# DA1469x register map
Vendor: Dialog; Series: DA1469x; File version: 1.2
CPU: CM33 r1p0, little endian, no MPU, FPU, 3 interrupt priority bits
Registers are 32-bit, read-write, reset 0x0 unless marked. A register's access mark holds for its fields unless they carry their own. Offsets are from the block's base; [hi:lo] are bit positions; {n}, {i} and the like mark numbered series; 'fields as' and 'values as' point back to an identical list.

## PDC — PDC registers
Base 0x50000200
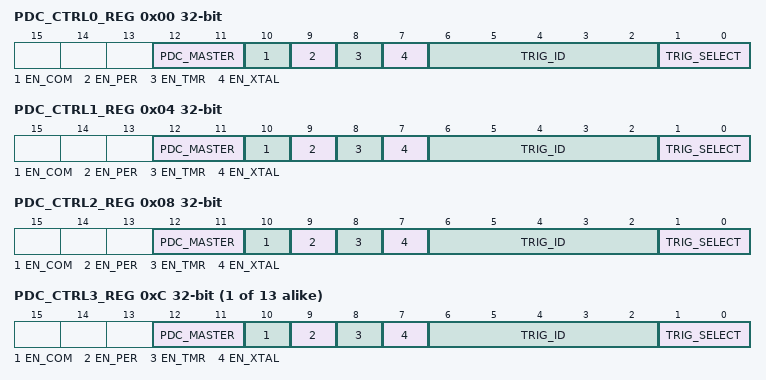
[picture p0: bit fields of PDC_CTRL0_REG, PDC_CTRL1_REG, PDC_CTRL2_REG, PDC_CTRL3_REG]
0x00 PDC_CTRL0_REG — PDC control register
  [12:11] PDC_MASTER — Chooses which master is triggered when waking up 0x0: entry is disabled. 0x1: PD_SYS is woken up and CM33 is triggered 0x2: PD_RAD is woken up and CMAC is triggered 0x3: PD_COM is woken up and SNC is triggered
  [10] EN_COM — If set, enables PD_COM for GPIO access. This bit is implied when PDC_MASTER=SNC
  [9] EN_PER — If set, enables PD_PER
  [8] EN_TMR — If set, enables PD_TMR
  [7] EN_XTAL — If set, the XTAL32M will be started
  [6:2] TRIG_ID — Selects which individual bit from the selected bank is used for wakup. For the peripheral banks, selected with TRIG_SELECT = 0x2 or 0x3, only the lower 4 bits are considered.
  [1:0] TRIG_SELECT — Selects which bank is used as wakeup trigger When TRIG_SELECT is 0x0, selects GPIO port0 through the WAKEUP block. When TRIG_SELECT is 0x1, selects GPIO port1 through the WAKEUP block. When TRIG_SELECT is 0x2 or 0x3, selects the peripheral IRQ. peripheral IRQ table: 0x0: Timer 0x1: Timer2 0x2: Timer3 0x3: Timer4 0x4: RTC Alarm/Rollover 0x5: RTC Timer 0x6: CMAC Timer OR wake up from CMAC debugger 0x7: Motor Controller 0x8: XTAL32MRDY_IRQ 0x9: RFDIAG_IRQ 0xA: CMAC2SYS_IRQ OR VBUS Present IRQ OR JTAG present OR Debounced IO 0xB: Sensor Node Controller 0xC to 0xE: reserved 0xF: Software trigger only
0x04 PDC_CTRL1_REG — PDC control register
  [12:11] PDC_MASTER — Chooses which master is triggered when waking up 0x0: entry is disabled. 0x1: PD_SYS is woken up and CM33 is triggered 0x2: PD_RAD is woken up and CMAC is triggered 0x3: PD_COM is woken up and SNC is triggered
  [10] EN_COM — If set, enables PD_COM for GPIO access. This bit is implied when PDC_MASTER=SNC
  [9] EN_PER — If set, enables PD_PER
  [8] EN_TMR — If set, enables PD_TMR
  [7] EN_XTAL — If set, the XTAL32M will be started
  [6:2] TRIG_ID — For description, see PDC_CTRL0_REG.TRIG_ID
  [1:0] TRIG_SELECT — For description, see PDC_CTRL0_REG.TRIG_SELECT
0x08 PDC_CTRL2_REG — PDC control register
  [12:11] PDC_MASTER — Chooses which master is triggered when waking up 0x0: entry is disabled. 0x1: PD_SYS is woken up and CM33 is triggered 0x2: PD_RAD is woken up and CMAC is triggered 0x3: PD_COM is woken up and SNC is triggered
  [10] EN_COM — IIf set, enables PD_COM for GPIO access. This bit is implied when PDC_MASTER=SNC
  [9] EN_PER — If set, enables PD_PER
  [8] EN_TMR — If set, enables PD_TMR
  [7] EN_XTAL — If set, the XTAL32M will be started
  [6:2] TRIG_ID — For description, see PDC_CTRL0_REG.TRIG_ID
  [1:0] TRIG_SELECT — For description, see PDC_CTRL0_REG.TRIG_SELECT
{0x0+4i} PDC_CTRL{i}_REG (i=3..15) — PDC control register
  fields as PDC_CTRL1_REG
0x80 PDC_ACKNOWLEDGE_REG — Clear a pending PDC bit
  [4:0] PDC_ACKNOWLEDGE wo — Writing to this field acknowledges the PDC IRQ request. The data controls which request is acknowledged
0x84 PDC_PENDING_REG — Shows any pending wakup event
  [15:0] PDC_PENDING ro — Indicates which IRQ ids are pending
0x88 PDC_PENDING_SNC_REG — Shows any pending IRQ to SNC
  [15:0] PDC_PENDING ro — Indicates which IRQ ids are pending towards the SensorNodeController
0x8C PDC_PENDING_CM33_REG — Shows any pending IRQ to CM33
  [15:0] PDC_PENDING ro — Indicates which IRQ ids are pending towards the CM33
0x90 PDC_PENDING_CMAC_REG — Shows any pending IRQ to CM33
  [15:0] PDC_PENDING ro — Indicates which IRQ ids are pending towards the CMAC
0x94 PDC_SET_PENDING_REG — Set a pending PDC bit
  [4:0] PDC_SET_PENDING wo — Writing to this field sets the PDC wakeup request and IRQ. The data controls which request is acknowledged

## PWMLED — PWMLED registers
Base 0x50030500
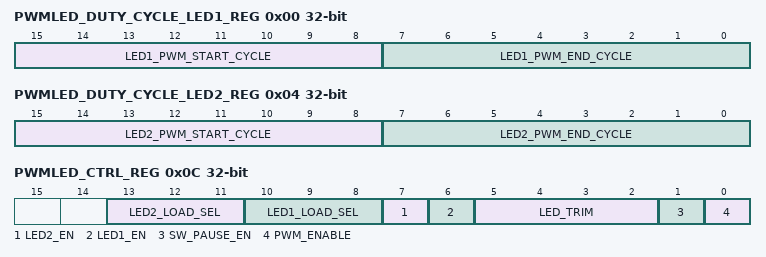
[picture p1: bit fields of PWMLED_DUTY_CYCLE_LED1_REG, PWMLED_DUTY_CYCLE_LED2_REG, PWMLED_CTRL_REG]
0x00 PWMLED_DUTY_CYCLE_LED1_REG — Defines duty cycle for PWM1
  [15:8] LED1_PWM_START_CYCLE — Defines the cycle in which the PWM becomes high. if start_cycle is larger than freq or end_cycle is equal to start_cycle, pwm out is always 0
  [7:0] LED1_PWM_END_CYCLE — Defines the cycle in which the PWM becomes low. If end_cycle is larger then freq and start_cycle is not larger then freq, output is always 1
0x04 PWMLED_DUTY_CYCLE_LED2_REG — Defines duty cycle for PWM2
  [15:8] LED2_PWM_START_CYCLE — Defines the cycle in which the PWM becomes high. if start_cycle is larger than freq or end_cycle is equal to start_cycle, pwm out is always 0
  [7:0] LED2_PWM_END_CYCLE — Defines the cycle in which the PWM becomes low. If end_cycle is larger then freq and start_cycle is not larger then freq, output is always 1
0x08 PWMLED_FREQUENCY_REG — Defines the PWM frequecny
  [7:0] LED_PWM_FREQUENCY — Defines the frequency of PWM 1 2, period = PWM_CLK * ( FREQ+1)
0x0C PWMLED_CTRL_REG — PWM Control register
  [13:11] LED2_LOAD_SEL — Defines LED2 output current: 2.5mA + (LED2_LOAD_SEL*2.5mA). Max = 20mA.
  [10:8] LED1_LOAD_SEL — Defines LED1 output current: 2.5mA + (LED1_LOAD_SEL*2.5mA). Max = 20mA.
  [7] LED2_EN — 0 = LED2 disabled 1 = LED2 enabled
  [6] LED1_EN — 0 = LED1 disabled 1 = LED1 enabled
  [5:2] LED_TRIM — LED current trimming bits
  [1] SW_PAUSE_EN — 0 = PWM are not blocked by SW 1 = PWM 1 and 2 are paused
  [0] PWM_ENABLE — 0 = PWM 1,2 are disabled 1 = PWM 1,2 are enabled
